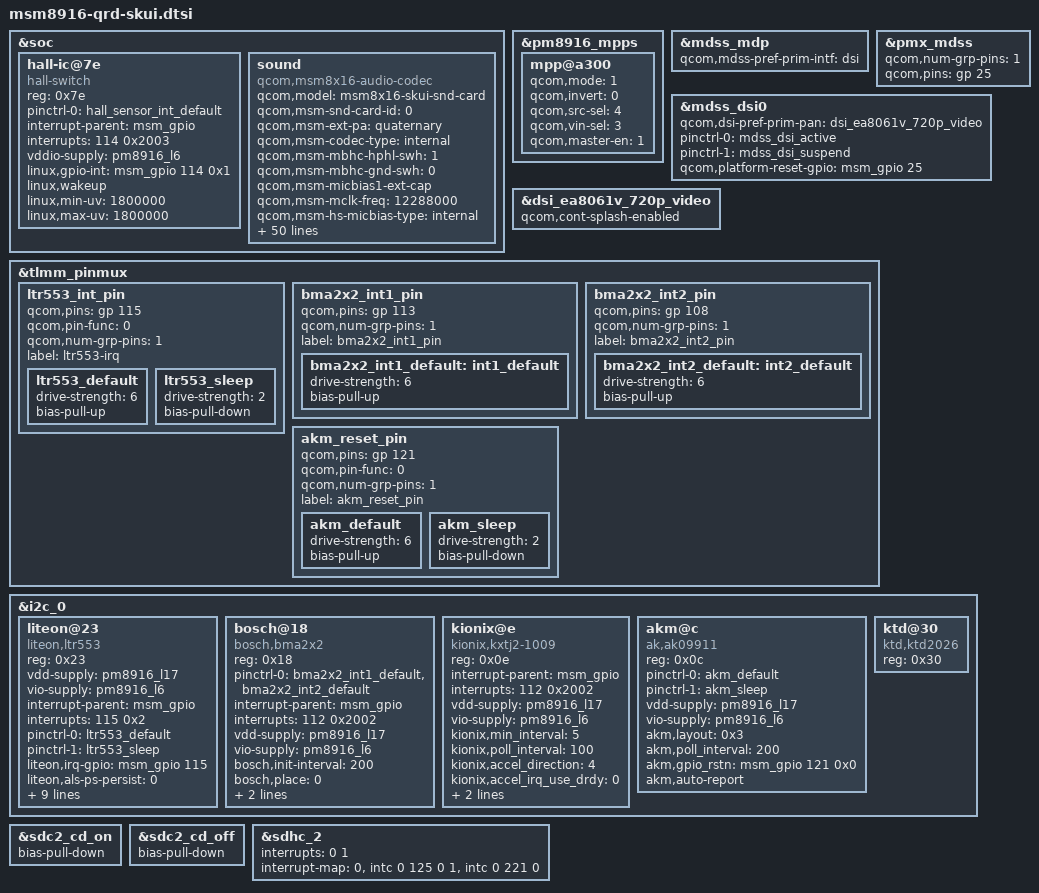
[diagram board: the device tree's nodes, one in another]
/* Copyright (c) 2014, The Linux Foundation. All rights reserved.
 *
 * This program is free software; you can redistribute it and/or modify
 * it under the terms of the GNU General Public License version 2 and
 * only version 2 as published by the Free Software Foundation.
 *
 * This program is distributed in the hope that it will be useful,
 * but WITHOUT ANY WARRANTY; without even the implied warranty of
 * MERCHANTABILITY or FITNESS FOR A PARTICULAR PURPOSE.  See the
 * GNU General Public License for more details.
 */

#include "msm8916-qrd.dtsi"
#include "dsi-panel-ea8061v-720p-video.dtsi"
#include "msm8916-camera-sensor-qrd-skui.dtsi"

&soc {
	/*gpio-leds {
		compatible = "gpio-leds";
		status = "okay";
		pinctrl-names = "default";
		pinctrl-0 = <&button_backlight_off>;

		keypad-backlight {
			gpios = <&msm_gpio 119 0>;
			label = "button-backlight";
			linux,default-trigger = "none";
		};
	};*/


	hall-ic@7e {
		compatible = "hall-switch";
    	    	reg = <0x7e>;
		pinctrl-names = "default";
		pinctrl-0 = <&hall_sensor_int_default>;
		interrupt-parent = <&msm_gpio>;
		interrupts = <114 0x2003>;
		vddio-supply = <&pm8916_l6>;
		linux,gpio-int = <&msm_gpio 114 0x1>;
		linux,wakeup;
		linux,min-uv = <1800000>;
		linux,max-uv = <1800000>;
	};


	sound {//<BEGIN><FFBAKK-105><2014.12.15>modify for tfa9890-pa;yangliang
		compatible = "qcom,msm8x16-audio-codec";
		qcom,model = "msm8x16-skui-snd-card";
		qcom,msm-snd-card-id = <0>;
		qcom,msm-ext-pa = "quaternary";
		qcom,msm-codec-type = "internal";
		qcom,msm-mbhc-hphl-swh = <1>;
		qcom,msm-mbhc-gnd-swh = <0>;
		qcom,msm-micbias1-ext-cap;
		qcom,msm-mclk-freq = <12288000>;
		qcom,msm-hs-micbias-type = "internal";
		qcom,audio-routing =
			"RX_BIAS", "MCLK",
			"SPK_RX_BIAS", "MCLK",
 			"INT_LDO_H", "MCLK",
			"MIC BIAS External", "Handset Mic",
 			"MIC BIAS Internal2", "Headset Mic",
 			"MIC BIAS External", "Secondary Mic",//yangliang change Internal1 to External for spk-voice using mic-3 to send signal
			"AMIC1", "MIC BIAS External",
 			"AMIC2", "MIC BIAS Internal2",
 			"AMIC3", "MIC BIAS External";//yangliang change Internal1 to External for spk-voice using mic-3 to send signal
 		pinctrl-names = "cdc_lines_act",
				"cdc_lines_sus",
				"cdc_lines_sec_ext_act",
				"cdc_lines_sec_ext_sus",
				"cdc_lines_quat_ext_act",
				"cdc_lines_quat_ext_sus";

		//qcom,ext-spk-amp-gpio = <&msm_gpio 16 0>;
		pinctrl-0 = <&cdc_pdm_lines_act>;
		pinctrl-1 = <&cdc_pdm_lines_sus>;
		pinctrl-2 = <&cdc_pdm_lines_act &cdc_ext_pa_act
						&cdc_ext_pa_ws_act>;
		pinctrl-3 = <&cdc_pdm_lines_sus &cdc_ext_pa_sus
						&cdc_ext_pa_ws_sus>;
		pinctrl-4 = <&cdc_pdm_lines_act &ext_cdc_tlmm_lines_act>;
		pinctrl-5 = <&cdc_pdm_lines_sus &ext_cdc_tlmm_lines_sus>;
		asoc-platform = <&pcm0>, <&pcm1>, <&voip>, <&voice>,
				<&loopback>, <&compress>, <&hostless>,
				<&afe>, <&lsm>, <&routing>, <&lpa>;
		asoc-platform-names = "msm-pcm-dsp.0", "msm-pcm-dsp.1",
				"msm-voip-dsp", "msm-pcm-voice", "msm-pcm-loopback",
				"msm-compress-dsp", "msm-pcm-hostless", "msm-pcm-afe",
				"msm-lsm-client", "msm-pcm-routing", "msm-pcm-lpa";
		asoc-cpu = <&dai_pri_auxpcm>, <&dai_hdmi>,
				<&dai_mi2s0>, <&dai_mi2s1>, <&dai_mi2s2>, <&dai_mi2s3>,
				<&sb_0_rx>, <&sb_0_tx>, <&sb_1_rx>, <&sb_1_tx>,
				<&sb_3_rx>, <&sb_3_tx>, <&sb_4_rx>, <&sb_4_tx>,
				<&bt_sco_rx>, <&bt_sco_tx>, <&int_fm_rx>, <&int_fm_tx>,
				<&afe_pcm_rx>, <&afe_pcm_tx>, <&afe_proxy_rx>, <&afe_proxy_tx>,
				<&incall_record_rx>, <&incall_record_tx>, <&incall_music_rx>,
				<&incall_music_2_rx>;
		asoc-cpu-names = "msm-dai-q6-auxpcm.1", "msm-dai-q6-hdmi.8",
				"msm-dai-q6-mi2s.0", "msm-dai-q6-mi2s.1",
				"msm-dai-q6-mi2s.2", "msm-dai-q6-mi2s.3",
				"msm-dai-q6-dev.16384", "msm-dai-q6-dev.16385",
				"msm-dai-q6-dev.16386", "msm-dai-q6-dev.16387",
				"msm-dai-q6-dev.16390", "msm-dai-q6-dev.16391",
				"msm-dai-q6-dev.16392", "msm-dai-q6-dev.16393",
				"msm-dai-q6-dev.12288", "msm-dai-q6-dev.12289",
				"msm-dai-q6-dev.12292", "msm-dai-q6-dev.12293",
				"msm-dai-q6-dev.224", "msm-dai-q6-dev.225",
				"msm-dai-q6-dev.241", "msm-dai-q6-dev.240",
				"msm-dai-q6-dev.32771", "msm-dai-q6-dev.32772",
				"msm-dai-q6-dev.32773", "msm-dai-q6-dev.32770";
		asoc-codec = <&stub_codec>, <&pm8916_tombak_dig>;
		asoc-codec-names = "msm-stub-codec.1", "tombak_codec";
	};
};

&pm8916_mpps {
	mpp@a300 { /* MPP 4 */
		/* Backlight PWM */
		qcom,mode = <1>;		/* Digital output */
		qcom,invert = <0>;		/* Disable invert */
		qcom,src-sel = <4>;		/* DTEST1 */
		//qcom,vin-sel = <0>;		/* VPH_PWR */
		qcom,vin-sel = <3>;		/* VIN3 1.9V */
		qcom,master-en = <1>;		/* Enable MPP */
	};
};

&mdss_mdp {
	qcom,mdss-pref-prim-intf = "dsi";
};

&pmx_mdss {
	qcom,num-grp-pins = <1>;
	qcom,pins = <&gp 25>;
};

&mdss_dsi0 {
	qcom,dsi-pref-prim-pan = <&dsi_ea8061v_720p_video>;
	pinctrl-names = "mdss_default", "mdss_sleep";
	pinctrl-0 = <&mdss_dsi_active>;
	pinctrl-1 = <&mdss_dsi_suspend>;

	qcom,platform-reset-gpio = <&msm_gpio 25 0>;
};

&dsi_ea8061v_720p_video {			//<Line><FFBAKK-105><20141202>modify LCD name for L9010;xiongdajun
       qcom,cont-splash-enabled;
};

&tlmm_pinmux {
	ltr553_int_pin {
		qcom,pins = <&gp 115>;	//xiongdajun modify gpio 20141205
		qcom,pin-func = <0>;
		qcom,num-grp-pins = <1>;
		label = "ltr553-irq";
		ltr553_default: ltr553_default {
			drive-strength = <6>;
			bias-pull-up;
		};
		ltr553_sleep: ltr553_sleep {
			drive-strength = <2>;
			bias-pull-down;
		};
	};
	bma2x2_int1_pin {
		qcom,pins = <&gp 113>;	//xiongdajun modify gpio 20141205
		qcom,num-grp-pins = <1>;
		label = "bma2x2_int1_pin";
		bma2x2_int1_default: int1_default {
			  drive-strength = <6>;
			  bias-pull-up;
		};
	};

	bma2x2_int2_pin {
		qcom,pins = <&gp 108>;	//xiongdajun modify gpio 20141205
		qcom,num-grp-pins = <1>;
		label = "bma2x2_int2_pin";
		bma2x2_int2_default: int2_default {
			  drive-strength = <6>;
			  bias-pull-up;
		};
	};
        akm_reset_pin {
            qcom,pins = <&gp 121>;	//xiongdajun modify gpio 20141205
            qcom,pin-func = <0>;
            qcom,num-grp-pins = <1>;
            label = "akm_reset_pin";
            akm_default: akm_default {
                 drive-strength = <6>;
                 bias-pull-up;
            };  
            akm_sleep: akm_sleep {
               drive-strength = <2>;
               bias-pull-down;
           };  
        };         
};

&i2c_0 { /* BLSP1 QUP2 */
	/*avago@39 {
		compatible = "avago,apds9930";
		reg = <0x39>;
		pinctrl-names = "default","sleep";
		pinctrl-0 = <&apds99xx_default>;
		pinctrl-1 = <&apds99xx_sleep>;
		interrupt-parent = <&msm_gpio>;
		interrupts = <113 0x2002>;
		vdd-supply = <&pm8916_l17>;
		vio-supply = <&pm8916_l6>;
		avago,irq-gpio = <&msm_gpio 113 0x2002>;
		avago,ps-threshold = <600>;
		avago,ps-hysteresis-threshold = <500>;
		avago,ps-pulse = <8>;
		avago,ps-pgain = <0>;
		avago,als-B = <186>;
		avago,als-C = <75>;
		avago,als-D = <129>;
		avago,ga-value = <768>;
	};*/
	/*liteon@23 {
		compatible = "liteon,ltr553";
		reg = <0x23>;
		pinctrl-names = "default","sleep";
		pinctrl-0 = <&ltr553_default>;
		pinctrl-1 = <&ltr553_sleep>;
		interrupt-parent = <&msm_gpio>;
		interrupts = <115 0x2>;		//xiongdajun modify gpio 20141205
		vdd-supply = <&pm8916_l17>;
		vio-supply = <&pm8916_l6>;
		liteon,intr = <&msm_gpio 115 0x2>;	//xiongdajun modify gpio 20141205
		liteon,highthr = <500>;
		liteon,lowthr = <400>;
		//LINE<JIRA_ID><DATE20141127><add ps cali data in dts>zenghaihui
		tinno,base_value = <0x0a>;
		tinno,threshold_high_offset = <0x60>;
		tinno,threshold_low_offset = <0x5A>;
	};*/

	liteon@23 {
		compatible = "liteon,ltr553";
		reg = <0x23>;
		vdd-supply = <&pm8916_l17>;
		vio-supply = <&pm8916_l6>;
		interrupt-parent = <&msm_gpio>;
		interrupts = <115 0x2>;
		pinctrl-names = "default","sleep";
		pinctrl-0 = <&ltr553_default>;
		pinctrl-1 = <&ltr553_sleep>;
		liteon,irq-gpio = <&msm_gpio 115 0x2>;
		liteon,als-ps-persist = <0>;
		liteon,ps-led = <0x7f>;
		liteon,ps-pulses = <4>;
		liteon,wakeup-threshold = <4>;
		liteon,als-integration-time = <0>;
		liteon,ps-distance-table = <1376 566 343 287 200 170 155>;
		//LINE<JIRA_ID><DATE20141127><add ps cali data in dts>zenghaihui
		tinno,base_value = <0x0a>;
		tinno,threshold_high_offset = <0x60>;
		tinno,threshold_low_offset = <0x5A>;
	};


	bosch@18 { /* Accelerometer sensor */
		compatible = "bosch,bma2x2";
		reg = <0x18>;
		pinctrl-names = "default";
		pinctrl-0 = <&bma2x2_int1_default &bma2x2_int2_default>;
		interrupt-parent = <&msm_gpio>;
		interrupts = <112 0x2002>;
		vdd-supply = <&pm8916_l17>;
		vio-supply = <&pm8916_l6>;
		bosch,init-interval = <200>;
		bosch,place = <0>;
		bosch,gpio-int1 = <&msm_gpio 113 0x2002>;		//xiongdajun modify gpio 20141205
		bosch,gpio-int2 = <&msm_gpio 108 0x2002>;		//xiongdajun modify gpio 20141205
	};
//Begin<REQ><JABALL-1500><20150523>add acceler of kinoix;xiongdajun
	kionix@e {
		compatible = "kionix,kxtj2-1009";
		reg = <0x0e>;
		interrupt-parent = <&msm_gpio>;
		interrupts = <112 0x2002>;
		vdd-supply = <&pm8916_l17>;
		vio-supply = <&pm8916_l6>;
		kionix,min_interval = <5>;
		kionix,poll_interval = <100>;
		kionix,accel_direction = <4>;
		kionix,accel_irq_use_drdy = <0>;
		kionix,accel_res = <12>;
		kionix,accel_g_range = <2>;
	};
//End<REQ><JABALL-1500><20150523>add acceler of kinoix;xiongdajun

	/*memsic@30 { 
		compatible = "memsic,mmc3416x";
		reg = <0x30>;
		vdd-supply = <&pm8916_l17>;
		vio-supply = <&pm8916_l6>;
		memsic,dir = "obverse-x-axis-forward";
		memsic,auto-report;
	};*/

	/*mpu6050@68 {
		compatible = "invn,mpu6050";
		reg = <0x68>;
		pinctrl-names = "mpu_default","mpu_sleep";
		pinctrl-0 = <&mpu6050_default>;
		pinctrl-1 = <&mpu6050_sleep>;
		interrupt-parent = <&msm_gpio>;
		interrupts = <115 0x2>;
		vdd-supply = <&pm8916_l17>;
		vlogic-supply = <&pm8916_l16>;
		vi2c-supply = <&pm8916_l6>;
		invn,gpio-int = <&msm_gpio 115 0x2>;
		invn,place = "Portrait Up Back Side";
                invn,accel_poll_ms = <200>;
                invn,gyro_poll_ms = <200>; 
	};*/
        /*xiongdajun del 20141205
        mpu6880@68{
            compatible = "invn,mpu6880";
            reg = <0x68>;
            interrupt-parent = <&msm_gpio>;
            interrupts = <115 0x2>;
            vdd-supply = <&pm8916_l17>;
            vio-supply = <&pm8916_l6>;
            invn,gpio-int = <&msm_gpio 115 0x2>;
            invn,gyro_poll_ms = <200>;
            invn,accel_poll_ms = <200>;
            invn,place = "Portrait Up";
        };*/

        akm@c {
            compatible = "ak,ak09911";
            reg = <0x0c>;
            pinctrl-names = "default","sleep";
            pinctrl-0 = <&akm_default>;
            pinctrl-1 = <&akm_sleep>;
            vdd-supply = <&pm8916_l17>;
            vio-supply = <&pm8916_l6>;
            akm,layout = <0x3>;
            akm,poll_interval = <200>;
            akm,gpio_rstn = <&msm_gpio 121 0x0>;	//xiongdajun modify gpio 20141205
            akm,auto-report;
        }; 

	ktd@30 { // ktd2026 field sensor //wangyanhui add 20141120
		compatible = "ktd,ktd2026";
		reg = <0x30>;
	};
};

&sdc2_cd_on {
	/delete-property/ bias-pull-up;
	bias-pull-down;
};

&sdc2_cd_off {
	/delete-property/ bias-disable;
	bias-pull-down;
};

&sdhc_2 {
	interrupts = <0 1>;
	interrupt-map = <0 &intc 0 125 0
		1 &intc 0 221 0>;
	interrupt-names = "hc_irq", "pwr_irq";
	/delete-property/ cd-gpios;
};

